# RockChip_RK3588 register map
Vendor: RockChip Electronics Co., Ltd.; Series: RK3588; File version: 0.1
Registers are 32-bit, read-write, no defined reset value unless marked. A register's access mark holds for its fields unless they carry their own. Offsets are from the block's base; [hi:lo] are bit positions; {n}, {i} and the like mark numbered series; <NAME> marks a mode.

## CRU_SBUS
Base 0xFD7D8000
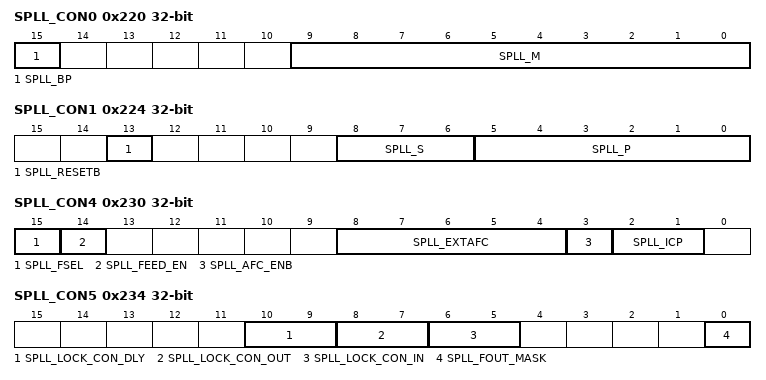
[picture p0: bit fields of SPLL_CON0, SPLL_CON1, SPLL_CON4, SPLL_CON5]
0x220 SPLL_CON0 — SPLL configuration register 0
  [15] SPLL_BP — BYPASS: Bypass mode control signal.
    1=BYPASS (bypass mode is enabled. (FOUT = FIN).); 0=NORMAL (PLL operates normally.)
  [9:0] SPLL_M — M: Division value of the 10-bit programmable main-divider. PLL has to be reset if M value is changed. 64 <= pll_m <= 1023
0x224 SPLL_CON1 — SPLL configuration register 1
  [13] SPLL_RESETB — RESETB: Power down control signal.
    0=NORMAL (RESETB=0 from 1, PLL starts its normal operation after lock time.); 1=POWER_DOWN (RESETB=1, power down mode is enabled and all digital blocks are reset.)
  [8:6] SPLL_S — Division value of the 3-bit programmable scaler. 0 <= pll_s <= 6
  [5:0] SPLL_P — P: Division value of the 6-bit programmable pre-divider. PLL has to be reset if P value is changed. 1 <= pll_p <= 63
0x230 SPLL_CON4 — SPLL configuration register 4
  [15] SPLL_FSEL — FSEL: Monitoring pin.
    0=FREF (FEED_OUT = FREF.); 1=FEED (FEED_OUT = FEED.)
  [14] SPLL_FEED_EN — FEED_EN: Monitoring pin.
    0=DISABLED (FEED_OUT is disabled.); 1=ENABLED (FEED_OUT is enabled.)
  [8:4] SPLL_EXTAFC — EXTAFC: Monitoring pin. If pll_afc_enb=1, AFC is disabled and VCO is calibrated manually by pll_extafc[4:0] for the test of VCO range.
  [3] SPLL_AFC_ENB — AFC_ENB: Monitoring pin.
    0=ENABLED (AFC is enabled and VCO is calibrated automatically.); 1=DISABLED (AFC is disabled and VCO is calibrated manually by pll_extafc[4:0] for the test of VCO range.)
  [2:1] SPLL_ICP — Charge-pump current control signal.
0x234 SPLL_CON5 — SPLL configuration register 5
  [10:9] SPLL_LOCK_CON_DLY — LOCK_CON_DLY: Lock detector setting of the detection resolution.
  [8:7] SPLL_LOCK_CON_OUT — LOCK_CON_OUT: Lock detector setting of the output margin.
  [6:5] SPLL_LOCK_CON_IN — LOCK_CON_IN: Lock detector setting of the input margin.
  [0] SPLL_FOUT_MASK — FOUT_MASK: Scaler's re-initialization time control pin.
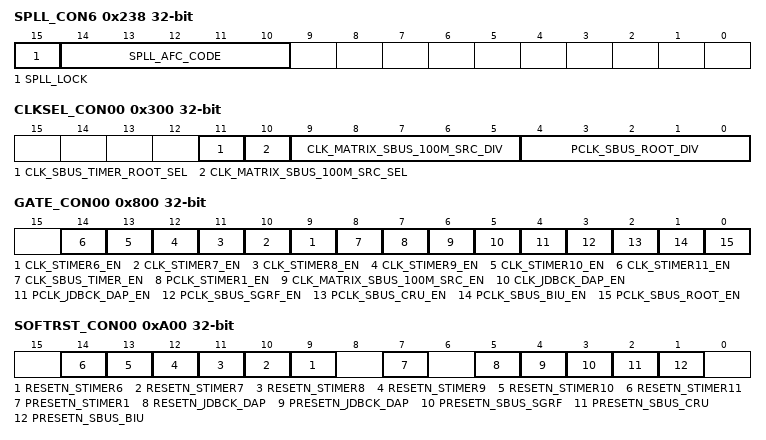
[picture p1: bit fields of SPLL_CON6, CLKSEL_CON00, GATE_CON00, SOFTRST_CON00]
0x238 SPLL_CON6 — SPLL configuration register 6
  [15] SPLL_LOCK — LOCK: PLL lock flag.
    0=UNLOCKED (PLL is unlocked.); 1=LOCKED (PLL is locked.)
  [14:10] SPLL_AFC_CODE — AFC_CODE: Monitoring pin. Output code of AFC(5 bits).
0x280 MODE_CON00 — Internal PLL mode select register 0
  [1:0] CLK_SPLL_MODE — clk_spll_mux clock mux.
    0=XIN_OSC0_FUNC; 1=CLK_SPLL; 2=CLK_DEEPSLOW
0x300 CLKSEL_CON00 — Internal clock select and division register 0
  [11] CLK_SBUS_TIMER_ROOT_SEL — clk_sbus_timer_root clock mux.
    0=XIN_OSC0_FUNC; 1=CLK_MATRIX_SBUS_100M_SRC
  [10] CLK_MATRIX_SBUS_100M_SRC_SEL — clk_matrix_sbus_100m_src clock mux.
    0=CLK_SPLL_MUX; 1=CLK_CPLL_MUX
  [9:5] CLK_MATRIX_SBUS_100M_SRC_DIV — Divide clk_matrix_sbus_100m_src by (div_con + 1).
  [4:0] PCLK_SBUS_ROOT_DIV — Divide pclk_sbus_root by (div_con + 1).
0x800 GATE_CON00 — Internal clock gate and division register 0
  [all] fields
    0=ENABLE; 1=DISABLE
  [n+3] CLK_STIMER{n}_EN (n=6..11) — clk_stimer{n} clock gating control.
  [8] CLK_SBUS_TIMER_EN — clk_sbus_timer_root clock gating control.
  [7] PCLK_STIMER1_EN — pclk_stimer1 clock gating control.
  [6] CLK_MATRIX_SBUS_100M_SRC_EN — clk_matrix_sbus_100m_src clock gating control.
  [5] CLK_JDBCK_DAP_EN — clk_jdbck_dap clock gating control.
  [4] PCLK_JDBCK_DAP_EN — pclk_jdbck_dap clock gating control.
  [3] PCLK_SBUS_SGRF_EN — pclk_sbus_sgrf clock gating control.
  [2] PCLK_SBUS_CRU_EN — pclk_sbus_cru clock gating control.
  [1] PCLK_SBUS_BIU_EN — pclk_sbus_biu clock gating control.
  [0] PCLK_SBUS_ROOT_EN — pclk_sbus_root clock gating control.
0xA00 SOFTRST_CON00 — Internal clock reset register 0
  [n+3] RESETN_STIMER{n} (n=6..11) — When high, reset relative logic
  [7] PRESETN_STIMER1 — When high, reset relative logic
  [5] RESETN_JDBCK_DAP — When high, reset relative logic
  [4] PRESETN_JDBCK_DAP — When high, reset relative logic
  [3] PRESETN_SBUS_SGRF — When high, reset relative logic
  [2] PRESETN_SBUS_CRU — When high, reset relative logic
  [1] PRESETN_SBUS_BIU — When high, reset relative logic
